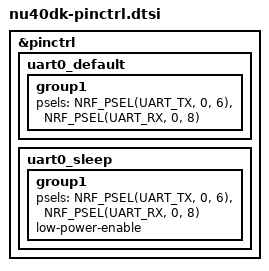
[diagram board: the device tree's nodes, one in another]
&pinctrl {
  // CLI 용 UART. 회로도상 미사용이고 핀 헤더로 나와 있는 핀을 쓴다.
  //   TX : P0.06
  //   RX : P0.08
  //
  uart0_default: uart0_default {
    group1 {
      psels = <NRF_PSEL(UART_TX, 0, 6)>,
              <NRF_PSEL(UART_RX, 0, 8)>;
    };
  };

  uart0_sleep: uart0_sleep {
    group1 {
      psels = <NRF_PSEL(UART_TX, 0, 6)>,
              <NRF_PSEL(UART_RX, 0, 8)>;
      low-power-enable;
    };
  };
};
